# EG32M0x register map
Vendor: EGmicro Ltd.; Series: EG32M0x; File version: 1.0
CPU: CM0 r0p0, little endian, no MPU, no FPU, 3 interrupt priority bits
Registers are 32-bit, read-write, reset 0x0 unless marked. A register's access mark holds for its fields unless they carry their own. Offsets are from the block's base; [hi:lo] are bit positions.

## TIMER4 — TIMER4 unit
Base 0x40020520
Same registers: TIMER5 0x40020580, TIMER6 0x400205E0
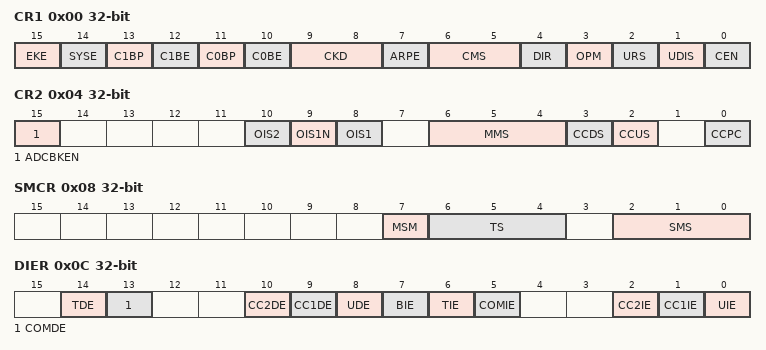
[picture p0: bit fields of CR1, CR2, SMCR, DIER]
0x00 CR1
  [15] EKE — External IO brake input switch
  [14] SYSE — System error brake switch
  [13] C1BP — Comparator 1 brake polarity
  [12] C1BE — Comparator 1 brake switch
  [11] C0BP — Comparator 0 brake polarity
  [10] C0BE — Comparator 0 brake switch
  [9:8] CKD — Clock frequency division factor
  [7] ARPE — Automatic reloading preloading allows bits
  [6:5] CMS — Select the center alignment mode
  [4] DIR — Counting direction
  [3] OPM — Single pulse mode
  [2] URS — Update request source
  [1] UDIS — Forbid updating
  [0] CEN — Enable counter
0x04 CR2
  [15] ADCBKEN — ADC brake switch
  [10] OIS2 — Output idle status 2
  [9] OIS1N — Output idle status 1
  [8] OIS1 — Output idle status 1
  [6:4] MMS — Master mode selection
  [3] CCDS — DMA selection for capture/comparison
  [2] CCUS — Capture/compare control update selection
  [0] CCPC — Capture/compare preloaded control bits
0x08 SMCR
  [7] MSM — Master/slave mode
  [6:4] TS — Trigger selection
  [2:0] SMS — Mode selection
0x0C DIER
  [14] TDE — Allows DMA requests to be triggered
  [13] COMDE — DMA requests for COM are allowed
  [10] CC2DE — DMA requests for capture/compare 2 are allowed
  [9] CC1DE — DMA requests for capture/compare 1 are allowed
  [8] UDE — DMA requests that allow updates
  [7] BIE — Allow brake break
  [6] TIE — The interrupt function was triggered
  [5] COMIE — Allow COM interrupt
  [2] CC2IE — Allows capture/compare 2 interrupts
  [1] CC1IE — Allows capture/compare 1 interrupts
  [0] UIE — Allow update interrupt
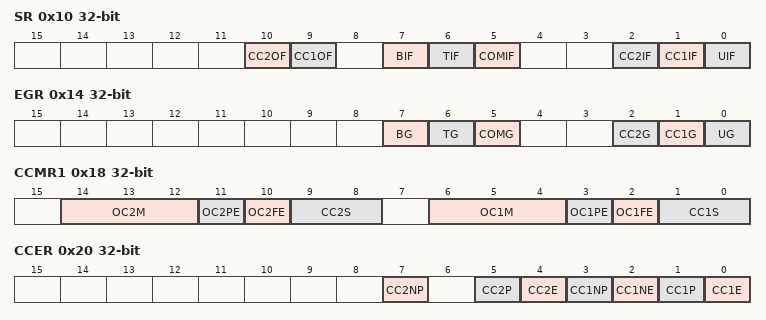
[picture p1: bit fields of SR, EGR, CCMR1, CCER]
0x10 SR
  [10] CC2OF — Capture 2 Repeat the capture tag
  [9] CC1OF — Capture 1 Repeat the capture tag
  [7] BIF — Brake interrupt flag
  [6] TIF — Trigger interrupt flag
  [5] COMIF — COM interrupt flag
  [2] CC2IF — Capture/compare 2 interrupt flags
  [1] CC1IF — Capture/compare 1 interrupt flags
  [0] UIF — Update interrupt flag
0x14 EGR
  [7] BG — Generating brake event
  [6] TG — Generate trigger event
  [5] COMG — Capture/compare event generation control updates
  [2] CC2G — Generate the capture/Compare 2 event
  [1] CC1G — Generate the capture/Compare 1 event
  [0] UG — Generate update event
0x18 CCMR1
  [14:12] OC2M — Output comparison 2 mode
  [11] OC2PE — Output comparison 2 Preload enable
  [10] OC2FE — Output comparison 2 Fast enable
  [9:8] CC2S — Capture/Compare 2 Select
  [6:4] OC1M — Output comparison 1 mode
  [3] OC1PE — Output comparison 1 Preload enable
  [2] OC1FE — Output comparison 1 Fast enable
  [1:0] CC1S — Capture/Compare 1 Select
0x20 CCER
  [7] CC2NP — Input/Capture 2 Complementary output polarity
  [5] CC2P — Input/Capture 2 Output polarity
  [4] CC2E — Input/Capture 2 Output Enable
  [3] CC1NP — Input/Capture 1 Complementary output polarity
  [2] CC1NE — Input/Capture 1 Enable complementary output
  [1] CC1P — Input/Capture 1 Output polarity
  [0] CC1E — Input/Capture 1 Output Enable
0x24 CNT
  [15:0] CNT — Counter value
0x28 PSC
  [15:0] PSC — The value of the pre-divider
0x2C ARR reset 0xFFFF
  [15:0] ARR — The value of automatic reloading
0x30 RCR
  [7:0] REP — Repeat the value of the counter
0x34 CCR1 reset 0xFFFF
  [15:0] CCR1 — Capture/compare values for channel 1
0x38 CCR2 reset 0xFFFF
  [15:0] CCR2 — Capture/compare values for channel 2
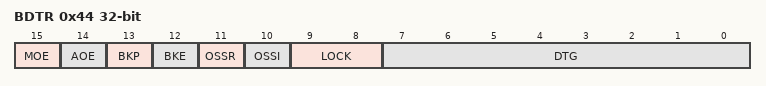
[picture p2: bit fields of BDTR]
0x44 BDTR
  [15] MOE — Master output is enabled
  [14] AOE — Automatic output is enabled
  [13] BKP — External IO brake input polarity
  [12] BKE — The brake function is enabled
  [11] OSSR — Off state in run mode
  [10] OSSI — Off state in idle mode
  [9:8] LOCK — Lock setting
  [7:0] DTG — Dead zone generator setting
